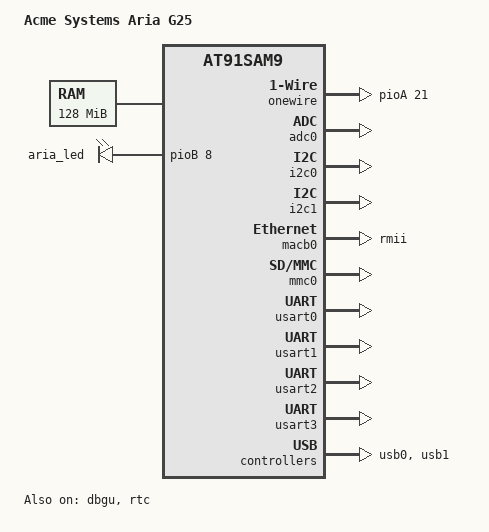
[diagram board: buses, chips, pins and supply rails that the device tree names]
/dts-v1/;
#include "at91sam9g25.dtsi"
/ {
	model = "Acme Systems Aria G25";
	compatible = "acme,ariag25", "atmel,at91sam9x5ek",
		     "atmel,at91sam9x5", "atmel,at91sam9";
	aliases {
		serial5 = &uart0;
		serial6 = &uart1;
	};
	chosen {
		bootargs = "console=ttyS0,115200 root=/dev/mmcblk0p2 rw rootwait";
	};
	memory@20000000 {
		reg = <0x20000000 0x8000000>;
	};
	clocks {
		slow_xtal {
			clock-frequency = <32768>;
		};
		main_xtal {
			clock-frequency = <12000000>;
		};
	};
	leds {
		compatible = "gpio-leds";
		aria_led {
			label = "aria_led";
			gpios = <&pioB 8 GPIO_ACTIVE_HIGH>;  
			linux,default-trigger = "heartbeat";
		};
	};
	onewire {
		compatible = "w1-gpio";
		gpios = <&pioA 21 GPIO_ACTIVE_LOW>;
		pinctrl-names = "default";
		pinctrl-0 = <&pinctrl_w1_0>;
	};
};
&adc0 {
	status = "okay";
	atmel,adc-channels-used = <0xf>;
};
&dbgu {
	status = "okay";
};
&i2c0 {
	status = "okay";
};
&i2c1 {
	status = "okay";
};
&macb0 {
	phy-mode = "rmii";
	local-mac-address = [00 00 00 00 00 00];
	status = "okay";
};
&mmc0 {
	pinctrl-0 = <
		&pinctrl_mmc0_slot0_clk_cmd_dat0
		&pinctrl_mmc0_slot0_dat1_3>;
	pinctrl-names = "default";
	status = "okay";
	slot@0 {
		reg = <0>;
		bus-width = <4>;
	};
};
&pinctrl {
	w1_0 {
		pinctrl_w1_0: w1_0-0 {
			atmel,pins = <0 21 0x0 0x1>;  
		};
	};
};
&rtc {
	status = "okay";
};
&tcb0 {
	timer@0 {
		compatible = "atmel,tcb-timer";
		reg = <0>;
	};
	timer@1 {
		compatible = "atmel,tcb-timer";
		reg = <1>;
	};
};
&uart0 {
	status = "disabled";
};
&uart1 {
	status = "disabled";
};
&usart0 {
	pinctrl-0 = <&pinctrl_usart0
		     &pinctrl_usart0_rts
		     &pinctrl_usart0_cts>;
	status = "okay";
};
&usart1 {
	pinctrl-0 = <&pinctrl_usart1
		    >;
	status = "okay";
};
&usart2 {
	pinctrl-0 = <&pinctrl_usart2>;
	status = "okay";
};
&usart3 {
	compatible = "atmel,at91sam9260-usart";
	reg = <0xf8028000 0x200>;
	interrupts = <8 4 5>;
	pinctrl-names = "default";
	pinctrl-0 = <&pinctrl_usart3
		    >;
	status = "okay";
};
&usb0 {
	status = "okay";
	num-ports = <3>;
};
&usb1 {
	status = "okay";
};
